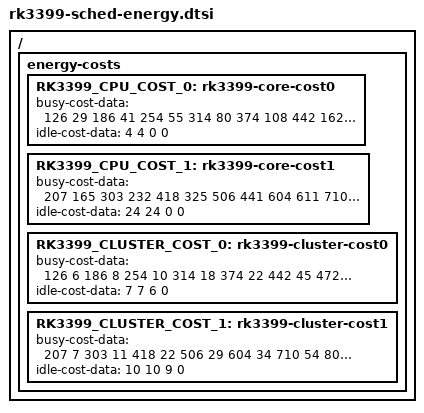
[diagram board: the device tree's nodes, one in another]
/*
 * Copyright (c) 2016 Fuzhou Rockchip Electronics Co., Ltd
 *
 * This file is dual-licensed: you can use it either under the terms
 * of the GPL or the X11 license, at your option. Note that this dual
 * licensing only applies to this file, and not this project as a
 * whole.
 *
 *  a) This library is free software; you can redistribute it and/or
 *     modify it under the terms of the GNU General Public License as
 *     published by the Free Software Foundation; either version 2 of the
 *     License, or (at your option) any later version.
 *
 *     This library is distributed in the hope that it will be useful,
 *     but WITHOUT ANY WARRANTY; without even the implied warranty of
 *     MERCHANTABILITY or FITNESS FOR A PARTICULAR PURPOSE.  See the
 *     GNU General Public License for more details.
 *
 * Or, alternatively,
 *
 *  b) Permission is hereby granted, free of charge, to any person
 *     obtaining a copy of this software and associated documentation
 *     files (the "Software"), to deal in the Software without
 *     restriction, including without limitation the rights to use,
 *     copy, modify, merge, publish, distribute, sublicense, and/or
 *     sell copies of the Software, and to permit persons to whom the
 *     Software is furnished to do so, subject to the following
 *     conditions:
 *
 *     The above copyright notice and this permission notice shall be
 *     included in all copies or substantial portions of the Software.
 *
 *     THE SOFTWARE IS PROVIDED "AS IS", WITHOUT WARRANTY OF ANY KIND,
 *     EXPRESS OR IMPLIED, INCLUDING BUT NOT LIMITED TO THE WARRANTIES
 *     OF MERCHANTABILITY, FITNESS FOR A PARTICULAR PURPOSE AND
 *     NONINFRINGEMENT. IN NO EVENT SHALL THE AUTHORS OR COPYRIGHT
 *     HOLDERS BE LIABLE FOR ANY CLAIM, DAMAGES OR OTHER LIABILITY,
 *     WHETHER IN AN ACTION OF CONTRACT, TORT OR OTHERWISE, ARISING
 *     FROM, OUT OF OR IN CONNECTION WITH THE SOFTWARE OR THE USE OR
 *     OTHER DEALINGS IN THE SOFTWARE.
 */

/ {
	energy-costs {
		RK3399_CPU_COST_0: rk3399-core-cost0 {
			busy-cost-data = <
				126    29	/*  408M */
				186    41	/*  600M */
				254    55	/*  816M */
				314    80	/* 1008M */
				374    108	/* 1200M */
				442    162	/* 1416M */
				472    206	/* 1512M */
			>;
			idle-cost-data = <
				4
				4
				0
				0
			>;
		};

		RK3399_CPU_COST_1: rk3399-core-cost1 {
			busy-cost-data = <
				207   165	/*  408MHz */
				303   232	/*  600MHz */
				418   325	/*  816MHz */
				506   441	/* 1008MHz */
				604   611	/* 1200MHz */
				710   839	/* 1416MHz */
				805   1061	/* 1608MHz */
				904   1385	/* 1800MHz */
				1024  1893	/* 2016MHz */
			>;
			idle-cost-data = <
				24
				24
				0
				0
			>;
		};

		RK3399_CLUSTER_COST_0: rk3399-cluster-cost0 {
			busy-cost-data = <
				126    6	/*  408M */
				186    8	/*  600M */
				254    10	/*  816M */
				314    18	/* 1008M */
				374    22	/* 1200M */
				442    45	/* 1416M */
				472    54	/* 1512M */
			>;
			idle-cost-data = <
				7
				7
				6
				0
			>;
		};

		RK3399_CLUSTER_COST_1: rk3399-cluster-cost1 {
			busy-cost-data = <
				207   7		/*  408MHz */
				303   11	/*  600MHz */
				418   22	/*  816MHz */
				506   29	/* 1008MHz */
				604   34	/* 1200MHz */
				710   54	/* 1416MHz */
				805   59	/* 1608MHz */
				904   63	/* 1800MHz */
				1024  78	/* 2016MHz */
			>;
			idle-cost-data = <
				10
				10
				9
				0
			>;
		};
	};
};
